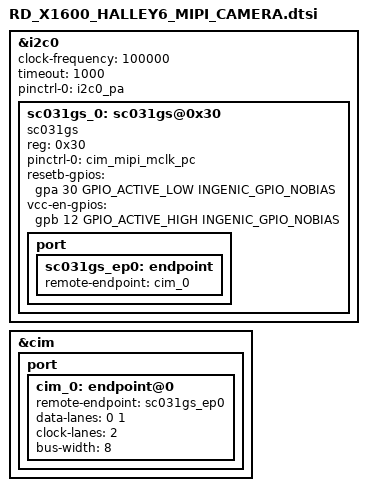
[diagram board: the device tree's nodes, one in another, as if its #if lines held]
#if defined (CONFIG_INGENIC_CIM_CAMERA_MIPI_SC031GS)
&i2c0 {
	status = "okay";
	clock-frequency = <100000>;
	timeout = <1000>;
	pinctrl-names = "default";
	pinctrl-0 = <&i2c0_pa>;

	sc031gs_0:sc031gs@0x30 {
		status = "okay";
		compatible = "sc031gs";
		reg = <0x30>;
		pinctrl-names = "default";
		pinctrl-0 = <&cim_mipi_mclk_pc>;

		resetb-gpios = <&gpa 30 GPIO_ACTIVE_LOW INGENIC_GPIO_NOBIAS>;
		vcc-en-gpios = <&gpb 12 GPIO_ACTIVE_HIGH INGENIC_GPIO_NOBIAS>;

		port {
			sc031gs_ep0:endpoint {
				remote-endpoint = <&cim_0>;
			};
		};
	};
};

&cim {
	status = "okay";
	port {
		cim_0: endpoint@0 {
			remote-endpoint = <&sc031gs_ep0>;
			data-lanes = <0 1>;
			clock-lanes = <2>;
			bus-width = <8>;
		};
	};
};
#elif defined (CONFIG_INGENIC_CIM_CAMERA_MIPI_GC2155)
&i2c0 {
	status = "okay";
	clock-frequency = <100000>;
	timeout = <1000>;
	pinctrl-names = "default";
	pinctrl-0 = <&i2c0_pa>;

	gc2155_0:gc2155@0x3c {
		status = "okay";
		compatible = "galaxycore,gc2155-mipi";
		reg = <0x3c>;
		pinctrl-names = "default";
		pinctrl-0 = <&cim_mclk_pa>;

        resetb-gpios = <&gpd 01 GPIO_ACTIVE_LOW INGENIC_GPIO_NOBIAS>;
        pwdn-gpios = <&gpd 00 GPIO_ACTIVE_LOW INGENIC_GPIO_NOBIAS>;
        vcc-en-gpios = <&gpb 26 GPIO_ACTIVE_HIGH INGENIC_GPIO_NOBIAS>;

		port {
			gc2155_ep0:endpoint {
				remote-endpoint = <&cim_0>;
			};
		};
	};
};

&cim {
	status = "okay";
	port {
		cim_0: endpoint@0 {
			remote-endpoint = <&gc2155_ep0>;
			data-lanes = <0 1>;
			clock-lanes = <2>;
			bus-width = <8>;
		};
	};
};
#elif defined (CONFIG_INGENIC_CIM_CAMERA_MIPI_SC132GS)
&i2c0 {
	status = "okay";
	clock-frequency = <100000>;
	timeout = <1000>;
	pinctrl-names = "default";
	pinctrl-0 = <&i2c0_pa>;

	sc132gs_0:sc132gs@0x30 {
		status = "okay";
		compatible = "sc132gs";
		reg = <0x30>;
		pinctrl-names = "default";
		pinctrl-0 = <&cim_mipi_mclk_pc>;

		resetb-gpios = <&gpa 30 GPIO_ACTIVE_LOW INGENIC_GPIO_NOBIAS>;
		vcc-en-gpios = <&gpb 12 GPIO_ACTIVE_HIGH INGENIC_GPIO_NOBIAS>;

		port {
			sc132gs_ep0:endpoint {
				remote-endpoint = <&cim_0>;
			};
		};
	};
};

&cim {
	status = "okay";
	port {
		cim_0: endpoint@0 {
			remote-endpoint = <&sc132gs_ep0>;
			data-lanes = <0 1>;
			clock-lanes = <2>;
			bus-width = <8>;
		};
	};
};
#else
error camera RD_X1600_HALLEY6_MIPI_CAMERA.dtsi
#endif
